# STM32G07x register map
File version: 1.3
CPU: CM0+ r0p0, little endian, no MPU, no FPU, 3 interrupt priority bits
Registers are 32-bit, read-write, reset 0x0 unless marked. A register's access mark holds for its fields unless they carry their own. Offsets are from the block's base; [hi:lo] are bit positions; {n}, {i} and the like mark numbered series.

## DMAMUX
Base 0x40020800
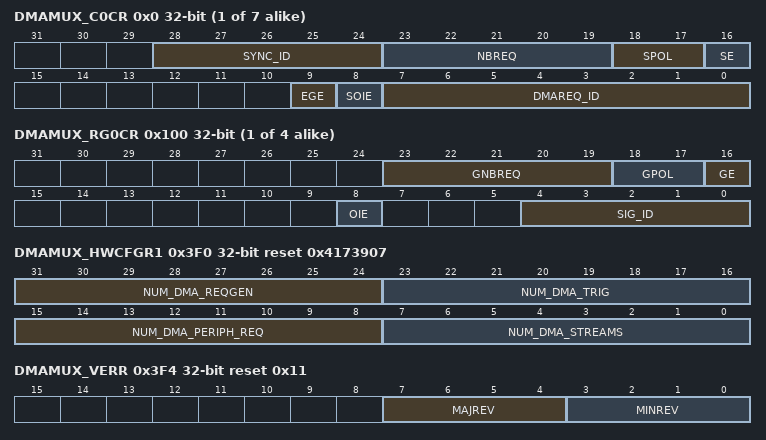
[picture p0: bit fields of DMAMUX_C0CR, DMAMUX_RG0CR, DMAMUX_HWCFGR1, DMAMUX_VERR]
{0x0+4i} DMAMUX_C{i}CR (i=0..6) — DMAMux - DMA request line multiplexer channel x control register
  [28:24] SYNC_ID — Synchronization input selected
  [23:19] NBREQ — Number of DMA requests to forward Defines the number of DMA requests forwarded before output event is generated. In synchronous mode, it also defines the number of DMA requests to forward after a synchronization event, then stop forwarding. The actual number of DMA requests forwarded is NBREQ+1. Note: This field can only be written when both SE and EGE bits are reset.
  [18:17] SPOL — Synchronization event type selector Defines the synchronization event on the selected synchronization input:
  [16] SE — Synchronous operating mode enable/disable
  [9] EGE — Event generation enable/disable
  [8] SOIE — Interrupt enable at synchronization event overrun
  [7:0] DMAREQ_ID — Input DMA request line selected
0x80 DMAMUX_CSR ro — DMAMUX request line multiplexer interrupt channel status register
  [6:0] SOF — Synchronization overrun event flag
0x84 DMAMUX_CFR wo — DMAMUX request line multiplexer interrupt clear flag register
  [6:0] CSOF — Clear synchronization overrun event flag
{0x100+4i} DMAMUX_RG{i}CR (i=0..3) — DMAMux - DMA request generator channel x control register
  [23:19] GNBREQ — Number of DMA requests to generate Defines the number of DMA requests generated after a trigger event, then stop generating. The actual number of generated DMA requests is GNBREQ+1. Note: This field can only be written when GE bit is reset.
  [18:17] GPOL — DMA request generator trigger event type selection Defines the trigger event on the selected DMA request trigger input
  [16] GE — DMA request generator channel enable/disable
  [8] OIE — Interrupt enable at trigger event overrun
  [4:0] SIG_ID — DMA request trigger input selected
0x140 DMAMUX_RGSR ro — DMAMux - DMA request generator status register
  [3:0] OF — Trigger event overrun flag The flag is set when a trigger event occurs on DMA request generator channel x, while the DMA request generator counter value is lower than GNBREQ. The flag is cleared by writing 1 to the corresponding COFx bit in DMAMUX_RGCFR register.
0x144 DMAMUX_RGCFR wo — DMAMux - DMA request generator clear flag register
  [3:0] COF — Clear trigger event overrun flag Upon setting, this bit clears the corresponding overrun flag OFx in the DMAMUX_RGCSR register.
0x3EC DMAMUX_HWCFGR2 ro reset 0x17 — DMAMUX hardware configuration 2 register
  [7:0] NUM_DMA_EXT_REQ — Number of DMA request trigger inputs
0x3F0 DMAMUX_HWCFGR1 ro reset 0x4173907 — DMAMUX hardware configuration 1 register
  [31:24] NUM_DMA_REQGEN — number of DMA request generator channels
  [23:16] NUM_DMA_TRIG — number of synchronization inputs
  [15:8] NUM_DMA_PERIPH_REQ — number of DMA request lines from peripherals
  [7:0] NUM_DMA_STREAMS — number of DMA request line multiplexer (output) channels
0x3F4 DMAMUX_VERR ro reset 0x11 — DMAMUX version register
  [7:4] MAJREV — Major IP revision
  [3:0] MINREV — Minor IP revision
0x3F8 DMAMUX_IPIDR ro reset 0x100011 — DMAMUX IP identification register
  [31:0] ID — IP identification
0x3FC DMAMUX_SIDR ro reset 0xA3C5DD01 — DMAMUX size identification register
  [31:0] SID — Size identification

## GPIOA — General-purpose I/Os
Base 0x50000000
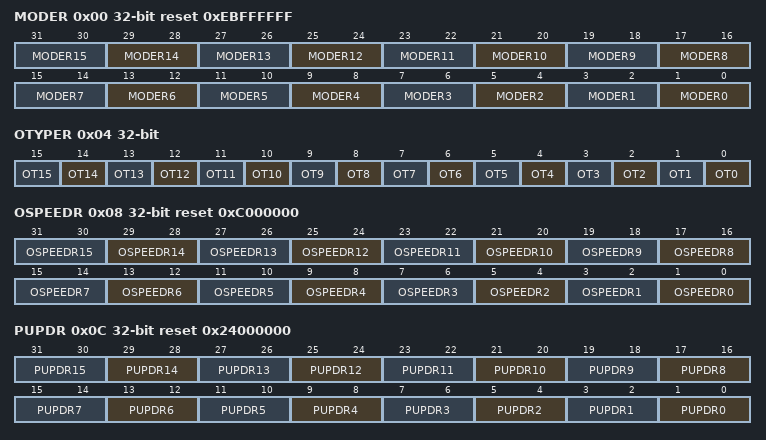
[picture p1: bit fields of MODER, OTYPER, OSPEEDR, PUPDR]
0x00 MODER reset 0xEBFFFFFF — GPIO port mode register
  [2n+1:2n] MODER{n} (n=0..15) — Port x configuration bits (y = 0..15)
0x04 OTYPER — GPIO port output type register
  [n] OT{n} (n=0..15) — Port x configuration bits (y = 0..15)
0x08 OSPEEDR reset 0xC000000 — GPIO port output speed register
  [2n+1:2n] OSPEEDR{n} (n=0..15) — Port x configuration bits (y = 0..15)
0x0C PUPDR reset 0x24000000 — GPIO port pull-up/pull-down register
  [2n+1:2n] PUPDR{n} (n=0..15) — Port x configuration bits (y = 0..15)
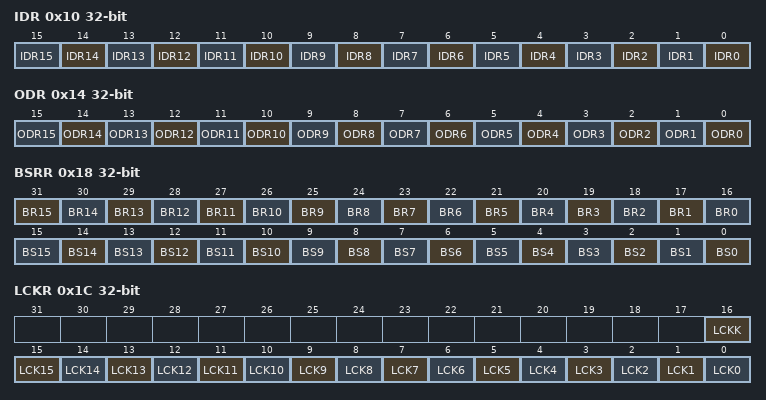
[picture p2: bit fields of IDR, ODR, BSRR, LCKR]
0x10 IDR ro — GPIO port input data register
  [n] IDR{n} (n=0..15) — Port input data (y = 0..15)
0x14 ODR — GPIO port output data register
  [n] ODR{n} (n=0..15) — Port output data (y = 0..15)
0x18 BSRR wo — GPIO port bit set/reset register
  [n+16] BR{n} (n=1..15) — Port x reset bit y (y = 0..15)
  [16] BR0 — Port x set bit y (y= 0..15)
  [n] BS{n} (n=0..15) — Port x set bit y (y= 0..15)
0x1C LCKR — GPIO port configuration lock register
  [16] LCKK — Port x lock bit y (y= 0..15)
  [n] LCK{n} (n=0..15) — Port x lock bit y (y= 0..15)
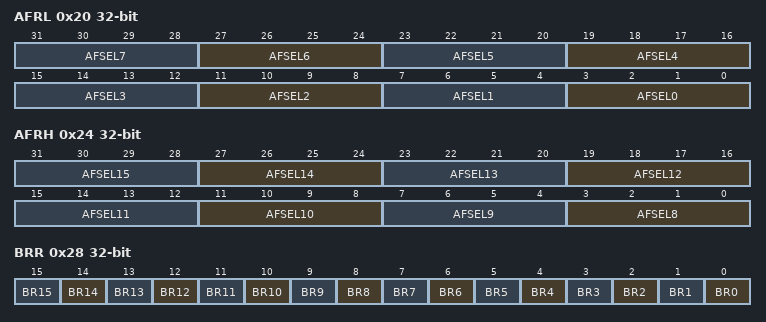
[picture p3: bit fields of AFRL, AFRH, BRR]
0x20 AFRL — GPIO alternate function low register
  [4n+3:4n] AFSEL{n} (n=0..7) — Alternate function selection for port x bit y (y = 0..7)
0x24 AFRH — GPIO alternate function high register
  [4n-29:4n-32] AFSEL{n} (n=8..15) — Alternate function selection for port x bit y (y = 8..15)
0x28 BRR wo — port bit reset register
  [n] BR{n} (n=0..15) — Port Reset bit

## GPIOB — General-purpose I/Os
Base 0x50000400
Same registers: GPIOC 0x50000800, GPIOD 0x50000C00, GPIOF 0x50001400
Registers as GPIOA; these are added or differ:
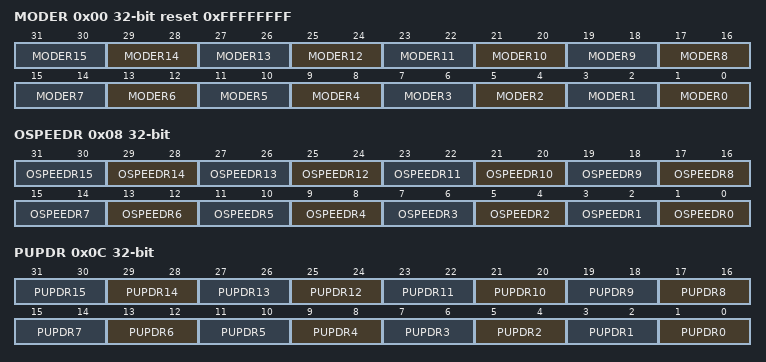
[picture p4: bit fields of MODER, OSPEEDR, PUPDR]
0x00 MODER reset 0xFFFFFFFF — GPIO port mode register
  [2n+1:2n] MODER{n} (n=0..15) — Port x configuration bits (y = 0..15)
0x08 OSPEEDR — GPIO port output speed register
  [2n+1:2n] OSPEEDR{n} (n=0..15) — Port x configuration bits (y = 0..15)
0x0C PUPDR — GPIO port pull-up/pull-down register
  [2n+1:2n] PUPDR{n} (n=0..15) — Port x configuration bits (y = 0..15)
